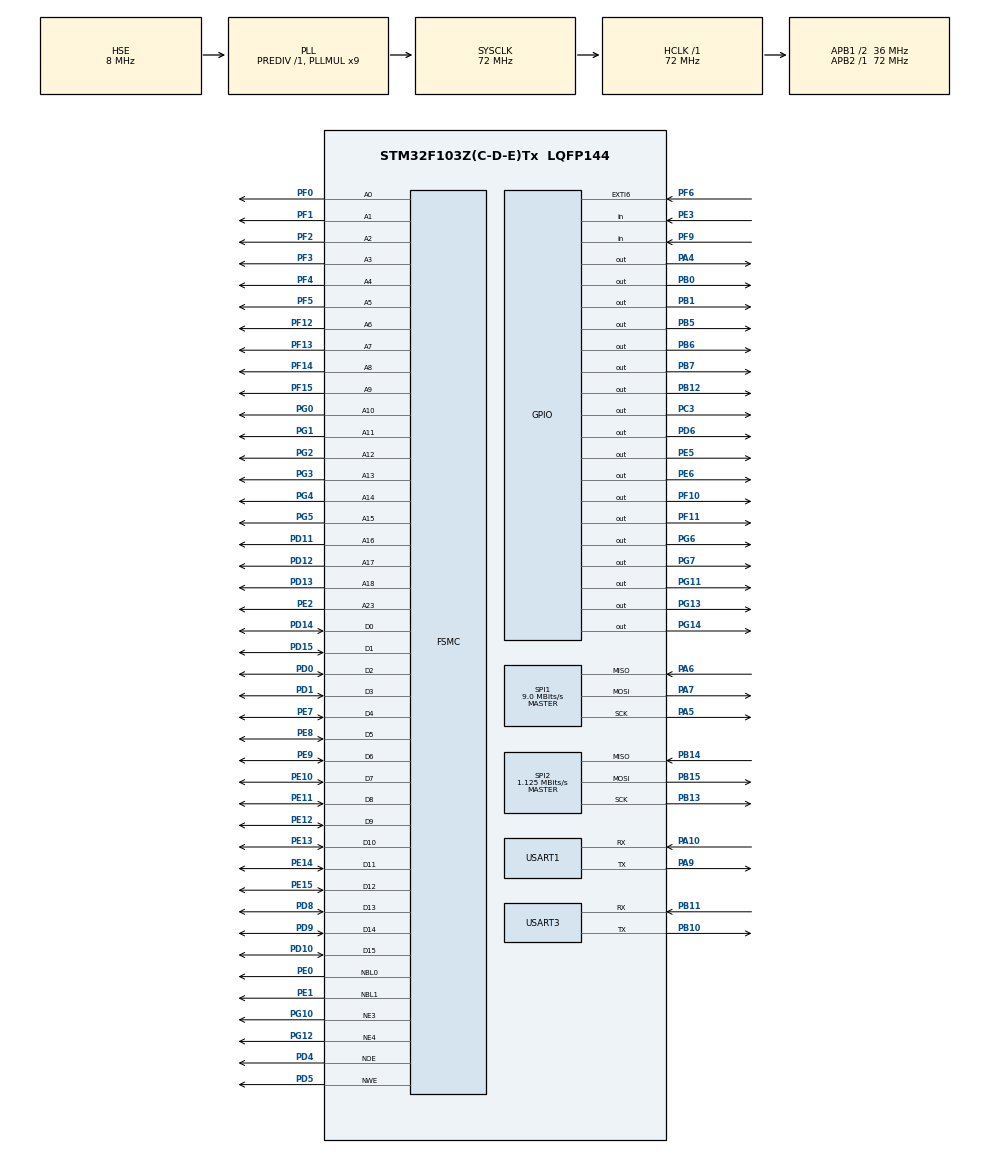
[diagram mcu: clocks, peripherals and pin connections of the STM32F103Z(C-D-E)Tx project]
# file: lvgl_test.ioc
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Dma.Request0=USART3_RX
Dma.Request1=USART1_RX
Dma.USART1_RX.1.Direction=DMA_PERIPH_TO_MEMORY
Dma.USART1_RX.1.Instance=DMA1_Channel5
Dma.USART1_RX.1.MemDataAlignment=DMA_MDATAALIGN_BYTE
Dma.USART1_RX.1.MemInc=DMA_MINC_ENABLE
Dma.USART1_RX.1.Mode=DMA_CIRCULAR
Dma.USART1_RX.1.PeriphDataAlignment=DMA_PDATAALIGN_BYTE
Dma.USART1_RX.1.PeriphInc=DMA_PINC_DISABLE
Dma.USART1_RX.1.Priority=DMA_PRIORITY_HIGH
Dma.USART3_RX.0.Direction=DMA_PERIPH_TO_MEMORY
Dma.USART3_RX.0.Instance=DMA1_Channel3
Dma.USART3_RX.0.MemDataAlignment=DMA_MDATAALIGN_BYTE
Dma.USART3_RX.0.MemInc=DMA_MINC_ENABLE
Dma.USART3_RX.0.Mode=DMA_CIRCULAR
Dma.USART3_RX.0.PeriphDataAlignment=DMA_PDATAALIGN_BYTE
Dma.USART3_RX.0.PeriphInc=DMA_PINC_DISABLE
Dma.USART3_RX.0.Priority=DMA_PRIORITY_HIGH
FREERTOS.Tasks01=defaultTask,24,128,StartDefaultTask,Default,NULL,Dynamic,NULL,NULL
FREERTOS.configCHECK_FOR_STACK_OVERFLOW=2
FREERTOS.configTOTAL_HEAP_SIZE=1024*15
FSMC.AddressSetupTime1=1
FSMC.AddressSetupTime2=2
FSMC.BusTurnAroundDuration1=0
FSMC.BusTurnAroundDuration2=1
FSMC.DataSetupTime1=4
FSMC.DataSetupTime2=2
FSMC.ExtendedAddressSetupTime2=2
FSMC.ExtendedBusTurnAroundDuration2=1
FSMC.ExtendedDataSetupTime2=2
FSMC.ExtendedMode2=FSMC_EXTENDED_MODE_ENABLE
FSMC.WriteOperation2=FSMC_WRITE_OPERATION_ENABLE
Mcu.Family=STM32F1
Mcu.Name=STM32F103Z(C-D-E)Tx
Mcu.Package=LQFP144
NVIC.DMA1_Channel3_IRQn=true\:5\:0\:false\:false\:true\:true\:false\:true\:true
NVIC.DMA1_Channel5_IRQn=true\:5\:0\:false\:false\:true\:true\:false\:true\:true
NVIC.PriorityGroup=NVIC_PRIORITYGROUP_4
NVIC.TIM2_IRQn=true\:14\:0\:true\:false\:true\:true\:true\:true\:true
NVIC.TIM6_IRQn=true\:15\:0\:false\:false\:true\:false\:false\:true\:true
NVIC.TimeBase=TIM6_IRQn
NVIC.TimeBaseIP=TIM6
NVIC.USART1_IRQn=true\:5\:0\:true\:false\:true\:true\:true\:true\:true
NVIC.USART3_IRQn=true\:5\:0\:false\:false\:true\:true\:true\:true\:true
OSC_IN.Mode=HSE-External-Oscillator
OSC_IN.Signal=RCC_OSC_IN
OSC_OUT.Mode=HSE-External-Oscillator
OSC_OUT.Signal=RCC_OSC_OUT
PA10.Mode=Asynchronous
PA10.Signal=USART1_RX
PA13.Mode=Serial_Wire
PA13.Signal=SYS_JTMS-SWDIO
PA14.Mode=Serial_Wire
PA14.Signal=SYS_JTCK-SWCLK
PA4.GPIO_ModeDefaultOutputPP=GPIO_MODE_OUTPUT_OD
PA4.GPIO_PuPd=GPIO_NOPULL
PA4.PinState=GPIO_PIN_SET
PA4.Signal=GPIO_Output
PA5.Mode=Full_Duplex_Master
PA5.Signal=SPI1_SCK
PA6.Mode=Full_Duplex_Master
PA6.Signal=SPI1_MISO
PA7.Mode=Full_Duplex_Master
PA7.Signal=SPI1_MOSI
PA9.Mode=Asynchronous
PA9.Signal=USART1_TX
PB0.PinState=GPIO_PIN_SET
PB0.Signal=GPIO_Output
PB1.PinState=GPIO_PIN_SET
PB1.Signal=GPIO_Output
PB10.Mode=Asynchronous
PB10.Signal=USART3_TX
PB11.Mode=Asynchronous
PB11.Signal=USART3_RX
PB12.Signal=GPIO_Output
PB13.Mode=Full_Duplex_Master
PB13.Signal=SPI2_SCK
PB14.Mode=Full_Duplex_Master
PB14.Signal=SPI2_MISO
PB15.Mode=Full_Duplex_Master
PB15.Signal=SPI2_MOSI
PB5.PinState=GPIO_PIN_SET
PB5.Signal=GPIO_Output
PB6.GPIO_ModeDefaultOutputPP=GPIO_MODE_OUTPUT_OD
PB6.GPIO_PuPd=GPIO_NOPULL
PB6.GPIO_Speed=GPIO_SPEED_FREQ_HIGH
PB6.PinState=GPIO_PIN_SET
PB6.Signal=GPIO_Output
PB7.GPIO_ModeDefaultOutputPP=GPIO_MODE_OUTPUT_OD
PB7.GPIO_PuPd=GPIO_NOPULL
PB7.GPIO_Speed=GPIO_SPEED_FREQ_HIGH
PB7.Signal=GPIO_Output
PC14-OSC32_IN.Mode=LSE-External-Oscillator
PC14-OSC32_IN.Signal=RCC_OSC32_IN
PC15-OSC32_OUT.Mode=LSE-External-Oscillator
PC15-OSC32_OUT.Signal=RCC_OSC32_OUT
PC3.Signal=GPIO_Output
PD0.Signal=FSMC_D2_DA2
PD1.Signal=FSMC_D3_DA3
PD10.Signal=FSMC_D15_DA15
PD11.Signal=FSMC_A16_CLE
PD12.Signal=FSMC_A17_ALE
PD13.Signal=FSMC_A18
PD14.Signal=FSMC_D0_DA0
PD15.Signal=FSMC_D1_DA1
PD4.Signal=FSMC_NOE
PD5.Signal=FSMC_NWE
PD6.GPIO_ModeDefaultOutputPP=GPIO_MODE_OUTPUT_OD
PD6.GPIO_PuPd=GPIO_NOPULL
PD6.GPIO_Speed=GPIO_SPEED_FREQ_LOW
PD6.PinState=GPIO_PIN_SET
PD6.Signal=GPIO_Output
PD8.Signal=FSMC_D13_DA13
PD9.Signal=FSMC_D14_DA14
PE0.Signal=FSMC_NBL0
PE1.Signal=FSMC_NBL1
PE10.Signal=FSMC_D7_DA7
PE11.Signal=FSMC_D8_DA8
PE12.Signal=FSMC_D9_DA9
PE13.Signal=FSMC_D10_DA10
PE14.Signal=FSMC_D11_DA11
PE15.Signal=FSMC_D12_DA12
PE2.Signal=FSMC_A23
PE3.GPIO_PuPd=GPIO_PULLUP
PE3.Signal=GPIO_Input
PE5.GPIO_ModeDefaultOutputPP=GPIO_MODE_OUTPUT_OD
PE5.GPIO_PuPd=GPIO_NOPULL
PE5.Signal=GPIO_Output
PE6.Signal=GPIO_Output
PE7.Signal=FSMC_D4_DA4
PE8.Signal=FSMC_D5_DA5
PE9.Signal=FSMC_D6_DA6
PF0.Signal=FSMC_A0
PF1.Signal=FSMC_A1
PF10.GPIO_Speed=GPIO_SPEED_FREQ_MEDIUM
PF10.PinState=GPIO_PIN_SET
PF10.Signal=GPIO_Output
PF11.GPIO_Speed=GPIO_SPEED_FREQ_MEDIUM
PF11.PinState=GPIO_PIN_SET
PF11.Signal=GPIO_Output
PF12.Signal=FSMC_A6
PF13.Signal=FSMC_A7
PF14.Signal=FSMC_A8
PF15.Signal=FSMC_A9
PF2.Signal=FSMC_A2
PF3.Signal=FSMC_A3
PF4.Signal=FSMC_A4
PF5.Signal=FSMC_A5
PF6.Signal=GPXTI6
PF9.GPIO_PuPd=GPIO_PULLUP
PF9.Signal=GPIO_Input
PG0.Signal=FSMC_A10
PG1.Signal=FSMC_A11
PG10.Mode=NorPsramChipSelect3_2
PG10.Signal=FSMC_NE3
PG11.PinState=GPIO_PIN_SET
PG11.Signal=GPIO_Output
PG12.Mode=NorPsramChipSelect4_1
PG12.Signal=FSMC_NE4
PG13.Signal=GPIO_Output
PG14.Signal=GPIO_Output
PG2.Signal=FSMC_A12
PG3.Signal=FSMC_A13
PG4.Signal=FSMC_A14
PG5.Signal=FSMC_A15
PG6.GPIO_Speed=GPIO_SPEED_FREQ_MEDIUM
PG6.PinState=GPIO_PIN_SET
PG6.Signal=GPIO_Output
PG7.GPIO_Speed=GPIO_SPEED_FREQ_MEDIUM
PG7.PinState=GPIO_PIN_SET
PG7.Signal=GPIO_Output
ProjectManager.HeapSize=0x200
ProjectManager.StackSize=0x400
ProjectManager.TargetToolchain=CMake
RCC.AHBFreq_Value=72000000
RCC.APB1CLKDivider=RCC_HCLK_DIV2
RCC.APB1Freq_Value=36000000
RCC.APB1TimFreq_Value=72000000
RCC.APB2Freq_Value=72000000
RCC.APB2TimFreq_Value=72000000
RCC.HCLKFreq_Value=72000000
RCC.PLLMUL=RCC_PLL_MUL9
RCC.PLLSourceVirtual=RCC_PLLSOURCE_HSE
RCC.RTCClockSelection=RCC_RTCCLKSOURCE_LSE
RCC.SYSCLKFreq_VALUE=72000000
RCC.SYSCLKSource=RCC_SYSCLKSOURCE_PLLCLK
RCC.USBFreq_Value=72000000
RTC.Format=RTC_FORMAT_BIN
SH.FSMC_A0.0=FSMC_A0,19b-a2
SH.FSMC_A1.0=FSMC_A1,19b-a2
SH.FSMC_A10.0=FSMC_A10,19b-a2
SH.FSMC_A11.0=FSMC_A11,19b-a2
SH.FSMC_A12.0=FSMC_A12,19b-a2
SH.FSMC_A13.0=FSMC_A13,19b-a2
SH.FSMC_A14.0=FSMC_A14,19b-a2
SH.FSMC_A15.0=FSMC_A15,19b-a2
SH.FSMC_A16_CLE.0=FSMC_A16,19b-a2
SH.FSMC_A17_ALE.0=FSMC_A17,19b-a2
SH.FSMC_A18.0=FSMC_A18,19b-a2
SH.FSMC_A2.0=FSMC_A2,19b-a2
SH.FSMC_A23.0=FSMC_A23,A23_1
SH.FSMC_A3.0=FSMC_A3,19b-a2
SH.FSMC_A4.0=FSMC_A4,19b-a2
SH.FSMC_A5.0=FSMC_A5,19b-a2
SH.FSMC_A6.0=FSMC_A6,19b-a2
SH.FSMC_A7.0=FSMC_A7,19b-a2
SH.FSMC_A8.0=FSMC_A8,19b-a2
SH.FSMC_A9.0=FSMC_A9,19b-a2
SH.FSMC_D0_DA0.0=FSMC_D0,16b-d1
SH.FSMC_D0_DA0.1=FSMC_D0,16b-d2
SH.FSMC_D10_DA10.0=FSMC_D10,16b-d1
SH.FSMC_D10_DA10.1=FSMC_D10,16b-d2
SH.FSMC_D11_DA11.0=FSMC_D11,16b-d1
SH.FSMC_D11_DA11.1=FSMC_D11,16b-d2
SH.FSMC_D12_DA12.0=FSMC_D12,16b-d1
SH.FSMC_D12_DA12.1=FSMC_D12,16b-d2
SH.FSMC_D13_DA13.0=FSMC_D13,16b-d1
SH.FSMC_D13_DA13.1=FSMC_D13,16b-d2
SH.FSMC_D14_DA14.0=FSMC_D14,16b-d1
SH.FSMC_D14_DA14.1=FSMC_D14,16b-d2
SH.FSMC_D15_DA15.0=FSMC_D15,16b-d1
SH.FSMC_D15_DA15.1=FSMC_D15,16b-d2
SH.FSMC_D1_DA1.0=FSMC_D1,16b-d1
SH.FSMC_D1_DA1.1=FSMC_D1,16b-d2
SH.FSMC_D2_DA2.0=FSMC_D2,16b-d1
SH.FSMC_D2_DA2.1=FSMC_D2,16b-d2
SH.FSMC_D3_DA3.0=FSMC_D3,16b-d1
SH.FSMC_D3_DA3.1=FSMC_D3,16b-d2
SH.FSMC_D4_DA4.0=FSMC_D4,16b-d1
SH.FSMC_D4_DA4.1=FSMC_D4,16b-d2
SH.FSMC_D5_DA5.0=FSMC_D5,16b-d1
SH.FSMC_D5_DA5.1=FSMC_D5,16b-d2
SH.FSMC_D6_DA6.0=FSMC_D6,16b-d1
SH.FSMC_D6_DA6.1=FSMC_D6,16b-d2
SH.FSMC_D7_DA7.0=FSMC_D7,16b-d1
SH.FSMC_D7_DA7.1=FSMC_D7,16b-d2
SH.FSMC_D8_DA8.0=FSMC_D8,16b-d1
SH.FSMC_D8_DA8.1=FSMC_D8,16b-d2
SH.FSMC_D9_DA9.0=FSMC_D9,16b-d1
SH.FSMC_D9_DA9.1=FSMC_D9,16b-d2
SH.FSMC_NBL0.0=FSMC_NBL0,2ByteEnable2
SH.FSMC_NBL1.0=FSMC_NBL1,2ByteEnable2
SH.FSMC_NOE.0=FSMC_NOE,Lcd1
SH.FSMC_NOE.1=FSMC_NOE,Sram2
SH.FSMC_NWE.0=FSMC_NWE,Lcd1
SH.FSMC_NWE.1=FSMC_NWE,Sram2
SPI1.BaudRatePrescaler=SPI_BAUDRATEPRESCALER_8
SPI1.CalculateBaudRate=9.0 MBits/s
SPI1.Direction=SPI_DIRECTION_2LINES
SPI1.Mode=SPI_MODE_MASTER
SPI1.VirtualType=VM_MASTER
SPI2.BaudRatePrescaler=SPI_BAUDRATEPRESCALER_32
SPI2.CLKPhase=SPI_PHASE_2EDGE
SPI2.CLKPolarity=SPI_POLARITY_HIGH
SPI2.CalculateBaudRate=1.125 MBits/s
SPI2.Direction=SPI_DIRECTION_2LINES
SPI2.Mode=SPI_MODE_MASTER
SPI2.VirtualType=VM_MASTER
TIM2.AutoReloadPreload=TIM_AUTORELOAD_PRELOAD_ENABLE
TIM2.Period=999
TIM2.Prescaler=71
TIM7.Prescaler=72-1
USART1.VirtualMode=VM_ASYNC
USART3.VirtualMode=VM_ASYNC
VP_FREERTOS_VS_CMSIS_V2.Mode=CMSIS_V2
VP_RTC_VS_RTC_Activate.Mode=RTC_Enabled
VP_RTC_VS_RTC_Calendar.Mode=RTC_Calendar
VP_SYS_VS_tim6.Mode=TIM6
VP_TIM2_VS_ClockSourceINT.Mode=Internal
VP_TIM7_VS_ClockSourceINT.Mode=Enable_Timer
board=custom

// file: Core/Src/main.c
/* USER CODE BEGIN Header */
/**
 ******************************************************************************
 * @file           : main.c
 * @brief          : Main program body
 ******************************************************************************
 * @attention
 *
 * Copyright (c) 2026 STMicroelectronics.
 * All rights reserved.
 *
 * This software is licensed under terms that can be found in the LICENSE file
 * in the root directory of this software component.
 * If no LICENSE file comes with this software, it is provided AS-IS.
 *
 ******************************************************************************
 */
/* USER CODE END Header */
#include "main.h"
#include "cmsis_os.h"
#include "dma.h"
#include "rtc.h"
#include "spi.h"
#include "tim.h"
#include "usart.h"
#include "gpio.h"
#include "fsmc.h"

/* USER CODE BEGIN Includes */
#include "driver_lcd.h"
#include "driver_xpt2046.h"
#include "lvgl.h"
#include "hal/lv_hal_tick.h"
#include "lv_port_disp_template.h"
#include "lv_port_indev_template.h"
/* USER CODE END Includes */

void SystemClock_Config(void);
void MX_FREERTOS_Init(void);

int main(void) {

    /* MCU Configuration--------------------------------------------------------*/

    /* Reset of all peripherals, Initializes the Flash interface and the Systick. */
    HAL_Init();

    /* Configure the system clock */
    SystemClock_Config();

    /* Initialize all configured peripherals */
    MX_GPIO_Init();
    MX_DMA_Init();
    MX_FSMC_Init();
    MX_TIM2_Init();
    MX_TIM7_Init();
    MX_USART3_UART_Init();
    MX_USART1_UART_Init();
    MX_RTC_Init();
    MX_SPI1_Init();
    MX_SPI2_Init();

    /* Init scheduler */
    osKernelInitialize(); /* Call init function for freertos objects (in cmsis_os2.c) */
    MX_FREERTOS_Init();

    /* Start scheduler */
    osKernelStart();

    /* We should never get here as control is now taken by the scheduler */

    /* Infinite loop */
    while (1) {

    }
}

void SystemClock_Config(void) {
    RCC_OscInitTypeDef RCC_OscInitStruct = {0};
    RCC_ClkInitTypeDef RCC_ClkInitStruct = {0};
    RCC_PeriphCLKInitTypeDef PeriphClkInit = {0};

    /** Initializes the RCC Oscillators according to the specified parameters
     * in the RCC_OscInitTypeDef structure.
     */
    RCC_OscInitStruct.OscillatorType = RCC_OSCILLATORTYPE_HSE | RCC_OSCILLATORTYPE_LSE;
    RCC_OscInitStruct.HSEState = RCC_HSE_ON;
    RCC_OscInitStruct.HSEPredivValue = RCC_HSE_PREDIV_DIV1;
    RCC_OscInitStruct.LSEState = RCC_LSE_ON;
    RCC_OscInitStruct.HSIState = RCC_HSI_ON;
    RCC_OscInitStruct.PLL.PLLState = RCC_PLL_ON;
    RCC_OscInitStruct.PLL.PLLSource = RCC_PLLSOURCE_HSE;
    RCC_OscInitStruct.PLL.PLLMUL = RCC_PLL_MUL9;
    if (HAL_RCC_OscConfig(&RCC_OscInitStruct) != HAL_OK) {
        Error_Handler();
    }

    /** Initializes the CPU, AHB and APB buses clocks
     */
    RCC_ClkInitStruct.ClockType = RCC_CLOCKTYPE_HCLK | RCC_CLOCKTYPE_SYSCLK
                                  | RCC_CLOCKTYPE_PCLK1 | RCC_CLOCKTYPE_PCLK2;
    RCC_ClkInitStruct.SYSCLKSource = RCC_SYSCLKSOURCE_PLLCLK;
    RCC_ClkInitStruct.AHBCLKDivider = RCC_SYSCLK_DIV1;
    RCC_ClkInitStruct.APB1CLKDivider = RCC_HCLK_DIV2;
    RCC_ClkInitStruct.APB2CLKDivider = RCC_HCLK_DIV1;

    if (HAL_RCC_ClockConfig(&RCC_ClkInitStruct, FLASH_LATENCY_2) != HAL_OK) {
        Error_Handler();
    }
    PeriphClkInit.PeriphClockSelection = RCC_PERIPHCLK_RTC;
    PeriphClkInit.RTCClockSelection = RCC_RTCCLKSOURCE_LSE;
    if (HAL_RCCEx_PeriphCLKConfig(&PeriphClkInit) != HAL_OK) {
        Error_Handler();
    }
}

void HAL_TIM_PeriodElapsedCallback(TIM_HandleTypeDef *htim) {
    if (htim->Instance == TIM6) {
        HAL_IncTick();
    }
    /* USER CODE BEGIN Callback 1 */
    if (htim->Instance == TIM2) {
        lv_tick_inc(1);
    }
    /* USER CODE END Callback 1 */
}

void Error_Handler(void) {
    __disable_irq();
    while (1) {
    }
}

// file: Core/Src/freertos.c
/* USER CODE BEGIN Header */
/**
 ******************************************************************************
 * File Name          : freertos.c
 * Description        : Code for freertos applications
 ******************************************************************************
 * @attention
 *
 * Copyright (c) 2026 STMicroelectronics.
 * All rights reserved.
 *
 * This software is licensed under terms that can be found in the LICENSE file
 * in the root directory of this software component.
 * If no LICENSE file comes with this software, it is provided AS-IS.
 *
 ******************************************************************************
 */
/* USER CODE END Header */

#include "FreeRTOS.h"
#include "task.h"
#include "main.h"
#include "cmsis_os.h"

/* USER CODE BEGIN Includes */
#include "user_TaskInit.h"
/* USER CODE END Includes */

/* Definitions for defaultTask */
osThreadId_t defaultTaskHandle;
const osThreadAttr_t defaultTask_attributes = {
  .name = "defaultTask",
  .stack_size = 128 * 4,
  .priority = (osPriority_t) osPriorityNormal,
};

void StartDefaultTask(void *argument);

void MX_FREERTOS_Init(void); /* (MISRA C 2004 rule 8.1) */

/* Hook prototypes */
void vApplicationStackOverflowHook(xTaskHandle xTask, signed char *pcTaskName);

/* USER CODE BEGIN 4 */
#include "debug_func.h"
void vApplicationStackOverflowHook(xTaskHandle xTask, signed char *pcTaskName) {
    /* Run time stack overflow checking is performed if
    configCHECK_FOR_STACK_OVERFLOW is defined to 1 or 2. This hook function is
    called if a stack overflow is detected. */
    RTT_PRINTF("STACK OVERFLOW in %s!\r\n", pcTaskName);
    while (1);
}
/* USER CODE END 4 */

void MX_FREERTOS_Init(void) {

  /* Create the thread(s) */
  /* creation of defaultTask */
  defaultTaskHandle = osThreadNew(StartDefaultTask, NULL, &defaultTask_attributes);

  /* USER CODE BEGIN RTOS_THREADS */

    userTasksInit();
    /* add threads, ... */
  /* USER CODE END RTOS_THREADS */

}

void StartDefaultTask(void *argument)
{
    for (;;) {
        osDelay(1);
    }
}
